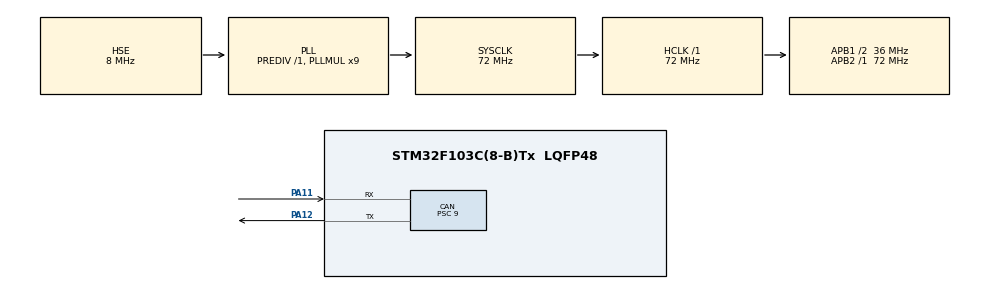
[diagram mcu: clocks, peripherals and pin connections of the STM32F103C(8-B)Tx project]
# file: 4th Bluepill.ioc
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CAN.ABOM=ENABLE
CAN.BS1=CAN_BS1_6TQ
CAN.BS2=CAN_BS2_1TQ
CAN.CalculateBaudRate=500000
CAN.CalculateTimeBit=2000
CAN.CalculateTimeQuantum=250.0
CAN.Prescaler=9
Mcu.Family=STM32F1
Mcu.Name=STM32F103C(8-B)Tx
Mcu.Package=LQFP48
NVIC.PriorityGroup=NVIC_PRIORITYGROUP_4
PA11.Mode=CAN_Activate
PA11.Signal=CAN_RX
PA12.Mode=CAN_Activate
PA12.Signal=CAN_TX
PA13.Mode=Serial_Wire
PA13.Signal=SYS_JTMS-SWDIO
PA14.Mode=Serial_Wire
PA14.Signal=SYS_JTCK-SWCLK
PD0-OSC_IN.Mode=HSE-External-Oscillator
PD0-OSC_IN.Signal=RCC_OSC_IN
PD1-OSC_OUT.Mode=HSE-External-Oscillator
PD1-OSC_OUT.Signal=RCC_OSC_OUT
ProjectManager.HeapSize=0x200
ProjectManager.StackSize=0x400
ProjectManager.TargetToolchain=STM32CubeIDE
RCC.AHBFreq_Value=72000000
RCC.APB1CLKDivider=RCC_HCLK_DIV2
RCC.APB1Freq_Value=36000000
RCC.APB1TimFreq_Value=72000000
RCC.APB2Freq_Value=72000000
RCC.APB2TimFreq_Value=72000000
RCC.HCLKFreq_Value=72000000
RCC.PLLMUL=RCC_PLL_MUL9
RCC.PLLSourceVirtual=RCC_PLLSOURCE_HSE
RCC.SYSCLKFreq_VALUE=72000000
RCC.SYSCLKSource=RCC_SYSCLKSOURCE_PLLCLK
RCC.USBFreq_Value=72000000
board=custom

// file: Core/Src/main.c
/* USER CODE BEGIN Header */
/**
  ******************************************************************************
  * @file           : main.c
  * @brief          : CAN telemetry node
  ******************************************************************************
  * @attention
  *
  * Copyright (c) 2026 STMicroelectronics.
  * All rights reserved.
  *
  * This software is licensed under terms that can be found in the LICENSE file
  * in the root directory of this software component.
  * If no LICENSE file comes with this software, it is provided AS-IS.
  *
  ******************************************************************************
  */
/* USER CODE END Header */
#include "main.h"

/* USER CODE BEGIN Includes */
#include "can_node.h"
/* USER CODE END Includes */

CAN_HandleTypeDef hcan;

void SystemClock_Config(void);
static void MX_GPIO_Init(void);
static void MX_CAN_Init(void);

int main(void)
{

  /* MCU Configuration--------------------------------------------------------*/

  /* Reset of all peripherals, Initializes the Flash interface and the Systick. */
  HAL_Init();

  /* Configure the system clock */
  SystemClock_Config();

  /* Initialize all configured peripherals */
  MX_GPIO_Init();
  MX_CAN_Init();
  /* USER CODE BEGIN 2 */
  can_node_init(&hcan);
  /* USER CODE END 2 */

  /* Infinite loop */
  while (1)
  {

    /* USER CODE BEGIN 3 */
    can_node_task();
  }
  /* USER CODE END 3 */
}

void SystemClock_Config(void)
{
  RCC_OscInitTypeDef RCC_OscInitStruct = {0};
  RCC_ClkInitTypeDef RCC_ClkInitStruct = {0};

  /** Initializes the RCC Oscillators according to the specified parameters
  * in the RCC_OscInitTypeDef structure.
  */
  RCC_OscInitStruct.OscillatorType = RCC_OSCILLATORTYPE_HSE;
  RCC_OscInitStruct.HSEState = RCC_HSE_ON;
  RCC_OscInitStruct.HSEPredivValue = RCC_HSE_PREDIV_DIV1;
  RCC_OscInitStruct.HSIState = RCC_HSI_ON;
  RCC_OscInitStruct.PLL.PLLState = RCC_PLL_ON;
  RCC_OscInitStruct.PLL.PLLSource = RCC_PLLSOURCE_HSE;
  RCC_OscInitStruct.PLL.PLLMUL = RCC_PLL_MUL9;
  if (HAL_RCC_OscConfig(&RCC_OscInitStruct) != HAL_OK)
  {
    Error_Handler();
  }

  /** Initializes the CPU, AHB and APB buses clocks
  */
  RCC_ClkInitStruct.ClockType = RCC_CLOCKTYPE_HCLK|RCC_CLOCKTYPE_SYSCLK
                              |RCC_CLOCKTYPE_PCLK1|RCC_CLOCKTYPE_PCLK2;
  RCC_ClkInitStruct.SYSCLKSource = RCC_SYSCLKSOURCE_PLLCLK;
  RCC_ClkInitStruct.AHBCLKDivider = RCC_SYSCLK_DIV1;
  RCC_ClkInitStruct.APB1CLKDivider = RCC_HCLK_DIV2;
  RCC_ClkInitStruct.APB2CLKDivider = RCC_HCLK_DIV1;

  if (HAL_RCC_ClockConfig(&RCC_ClkInitStruct, FLASH_LATENCY_2) != HAL_OK)
  {
    Error_Handler();
  }
}

static void MX_CAN_Init(void)
{

  hcan.Instance = CAN1;

  /*
   * Bit timing. PCLK1 = 36 MHz.
   *
   *   Prescaler 9 -> 250 ns per time quantum
   *   1 (sync) + 6 (BS1) + 1 (BS2) = 8 tq per bit -> 2 us -> 500 kbit/s
   *   Sample point = (1 + 6) / 8 = 87.5%
   *
   * Was Prescaler 8 / BS1 6 / BS2 2, which also gives exactly 500 kbit/s but
   * samples at 77.8%. The Nucleo hub samples at 87.5%, and a 9.7-point
   * mismatch eats the margin the bus needs for oscillator tolerance and
   * propagation delay. It works on a short bench harness and starts throwing
   * sporadic form and stuff errors as cables get longer.
   *
   * 87.5% is the CiA-recommended point. At 36 MHz PCLK1 there is no
   * combination with BS2 = 2 that reaches it exactly, so BS2 is 1 tq here.
   * bxCAN permits that; if you would rather keep more margin on the phase 2
   * segment, Prescaler 4 / BS1 14 / BS2 3 gives 83.3%, still far better than
   * where this started.
   */
  hcan.Init.Prescaler = 9;
  hcan.Init.Mode = CAN_MODE_NORMAL;
  hcan.Init.SyncJumpWidth = CAN_SJW_1TQ;
  hcan.Init.TimeSeg1 = CAN_BS1_6TQ;
  hcan.Init.TimeSeg2 = CAN_BS2_1TQ;
  hcan.Init.TimeTriggeredMode = DISABLE;

  /* Was DISABLE. One shorted wire or missing terminator drives the controller
     to bus-off, and without automatic recovery the node stays mute until it is
     power-cycled, with no outward sign that anything happened. */
  hcan.Init.AutoBusOff = ENABLE;

  hcan.Init.AutoWakeUp = DISABLE;

  /* One-shot transmission. For periodic telemetry this is the right choice:
     a frame that loses arbitration is better replaced by the next sample
     100 ms later than retried with data that is already stale. */
  hcan.Init.AutoRetransmission = DISABLE;

  hcan.Init.ReceiveFifoLocked = DISABLE;
  hcan.Init.TransmitFifoPriority = DISABLE;
  if (HAL_CAN_Init(&hcan) != HAL_OK)
  {
    Error_Handler();
  }

}

static void MX_GPIO_Init(void)
{

  /* GPIO Ports Clock Enable */
  __HAL_RCC_GPIOD_CLK_ENABLE();
  __HAL_RCC_GPIOA_CLK_ENABLE();

}

void Error_Handler(void)
{
  __disable_irq();
  while (1)
  {
  }
}
